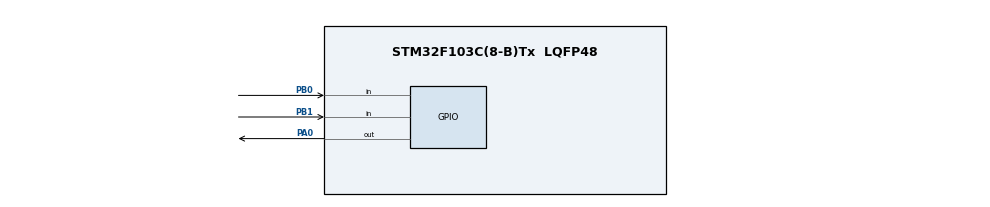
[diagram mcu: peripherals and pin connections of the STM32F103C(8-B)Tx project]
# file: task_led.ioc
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Mcu.Family=STM32F1
Mcu.Name=STM32F103C(8-B)Tx
Mcu.Package=LQFP48
NVIC.PriorityGroup=NVIC_PRIORITYGROUP_4
PA0-WKUP.Signal=GPIO_Output
PA13.Mode=Serial_Wire
PA13.Signal=SYS_JTMS-SWDIO
PA14.Mode=Serial_Wire
PA14.Signal=SYS_JTCK-SWCLK
PB0.GPIO_PuPd=GPIO_PULLUP
PB0.Signal=GPIO_Input
PB1.GPIO_PuPd=GPIO_PULLUP
PB1.Signal=GPIO_Input
ProjectManager.HeapSize=0x200
ProjectManager.StackSize=0x400
ProjectManager.TargetToolchain=STM32CubeIDE
RCC.APB1Freq_Value=8000000
RCC.APB2Freq_Value=8000000
board=custom

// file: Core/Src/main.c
	/* USER CODE BEGIN Header */
/**
  ******************************************************************************
  * @file           : main.c
  * @brief          : Main program body
  ******************************************************************************
  * @attention
  *
  * Copyright (c) 2025 STMicroelectronics.
  * All rights reserved.
  *
  * This software is licensed under terms that can be found in the LICENSE file
  * in the root directory of this software component.
  * If no LICENSE file comes with this software, it is provided AS-IS.
  *
  ******************************************************************************
  */
/* USER CODE END Header */
#include "main.h"
#include "gpio.h"

/* USER CODE BEGIN Includes */
#include "stm32f1xx_hal.h"
#include <stdbool.h> //bool要用这个库函数引入，下面有具体作用
/* USER CODE END Includes */

/* USER CODE BEGIN PV */
bool mode1 = true;  // 模式1：按键A单次按下翻转LED；模式2：按键A按住亮、松开灭
uint8_t keyA_state = 0;  // 按键A：0-未按下，1-按下（消抖后）
uint8_t keyB_state = 0;  // 按键B：0-未按下，1-按下（消抖后）
/* USER CODE END PV */

void SystemClock_Config(void);

int main(void)
{

  /* MCU Configuration--------------------------------------------------------*/

  /* Reset of all peripherals, Initializes the Flash interface and the Systick. */
  HAL_Init();

  /* Configure the system clock */
  SystemClock_Config();

  /* Initialize all configured peripherals */
  MX_GPIO_Init();
  HAL_Init();
  SystemClock_Config();

  /* Infinite loop */
  /* USER CODE BEGIN WHILE */
  while (1)
   {
     /* USER CODE BEGIN WHILE */
     // 按键B检测
     if (HAL_GPIO_ReadPin(GPIOB, GPIO_PIN_1) == GPIO_PIN_RESET) {  // 按键B按下（低电平）
       HAL_Delay(20);  // 消抖（阻塞式
       if (HAL_GPIO_ReadPin(GPIOB, GPIO_PIN_1) == GPIO_PIN_RESET) {
         keyB_state = 1;
         mode1 = !mode1;  // 切换模式
         while (HAL_GPIO_ReadPin(GPIOB, GPIO_PIN_1) == GPIO_PIN_RESET);  // 等待按键释放
       }
     } else {
       keyB_state = 0;
     }

     // 按键A检测：控制LED
     if (HAL_GPIO_ReadPin(GPIOB, GPIO_PIN_0) == GPIO_PIN_RESET) {  // 按键A按下（低电平）
       HAL_Delay(100);  // 软件消抖
       if (HAL_GPIO_ReadPin(GPIOB, GPIO_PIN_0) == GPIO_PIN_RESET) {
         keyA_state = 1;
         if (mode1) {
           // 模式1：单次按下翻转LED（不变）
           HAL_GPIO_TogglePin(GPIOA, GPIO_PIN_0);
         } else {
           // 模式2：按下时LED亮
           HAL_GPIO_WritePin(GPIOA, GPIO_PIN_0, GPIO_PIN_RESET);
         }
       }
     } else {
       keyA_state = 0;
       if (!mode1) {
         // 模式2：松开时LED灭
         HAL_GPIO_WritePin(GPIOA, GPIO_PIN_0, GPIO_PIN_SET);
       }
     }
     /* USER CODE END WHILE */

   }
 }

void SystemClock_Config(void)
{
  RCC_OscInitTypeDef RCC_OscInitStruct = {0};
  RCC_ClkInitTypeDef RCC_ClkInitStruct = {0};

  /** Initializes the RCC Oscillators according to the specified parameters
  * in the RCC_OscInitTypeDef structure.
  */
  RCC_OscInitStruct.OscillatorType = RCC_OSCILLATORTYPE_HSI;
  RCC_OscInitStruct.HSIState = RCC_HSI_ON;
  RCC_OscInitStruct.HSICalibrationValue = RCC_HSICALIBRATION_DEFAULT;
  RCC_OscInitStruct.PLL.PLLState = RCC_PLL_NONE;
  if (HAL_RCC_OscConfig(&RCC_OscInitStruct) != HAL_OK)
  {
    Error_Handler();
  }

  /** Initializes the CPU, AHB and APB buses clocks
  */
  RCC_ClkInitStruct.ClockType = RCC_CLOCKTYPE_HCLK|RCC_CLOCKTYPE_SYSCLK
                              |RCC_CLOCKTYPE_PCLK1|RCC_CLOCKTYPE_PCLK2;
  RCC_ClkInitStruct.SYSCLKSource = RCC_SYSCLKSOURCE_HSI;
  RCC_ClkInitStruct.AHBCLKDivider = RCC_SYSCLK_DIV1;
  RCC_ClkInitStruct.APB1CLKDivider = RCC_HCLK_DIV1;
  RCC_ClkInitStruct.APB2CLKDivider = RCC_HCLK_DIV1;

  if (HAL_RCC_ClockConfig(&RCC_ClkInitStruct, FLASH_LATENCY_0) != HAL_OK)
  {
    Error_Handler();
  }
}

void Error_Handler(void)
{
  __disable_irq();
  while (1)
  {
  }
}
